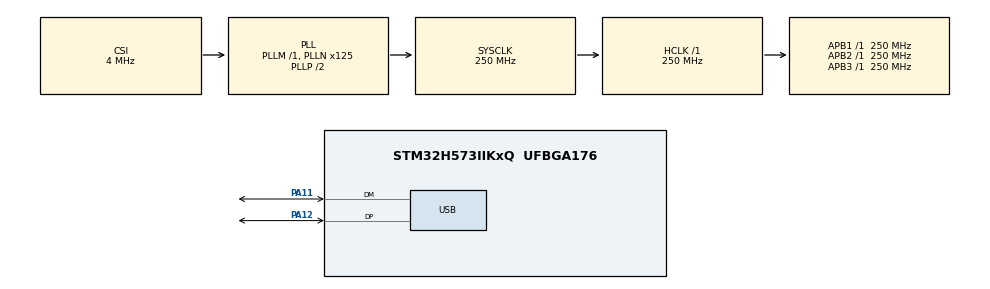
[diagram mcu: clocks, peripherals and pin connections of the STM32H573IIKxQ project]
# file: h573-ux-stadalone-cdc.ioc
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CORTEX_M33_NS.userName=CORTEX_M33
Mcu.Family=STM32H5
Mcu.Name=STM32H573IIKxQ
Mcu.Package=UFBGA176
NVIC.PriorityGroup=NVIC_PRIORITYGROUP_4
NVIC.USB_DRD_FS_IRQn=true\:0\:0\:false\:false\:true\:true\:true\:true
PA11.Mode=Device
PA11.Signal=USB_DM
PA12.Mode=Device
PA12.Signal=USB_DP
ProjectManager.HeapSize=0x200
ProjectManager.StackSize=0x400
ProjectManager.TargetToolchain=STM32CubeIDE
RCC.ADCFreq_Value=250000000
RCC.AHBFreq_Value=250000000
RCC.APB1Freq_Value=250000000
RCC.APB1TimFreq_Value=250000000
RCC.APB2Freq_Value=250000000
RCC.APB2TimFreq_Value=250000000
RCC.APB3Freq_Value=250000000
RCC.CSI_VALUE=4000000
RCC.CortexFreq_Value=250000000
RCC.EPOD_VALUE=4000000
RCC.HCLKFreq_Value=250000000
RCC.HSE_VALUE=25000000
RCC.HSI48_VALUE=48000000
RCC.HSI_VALUE=64000000
RCC.LSE_VALUE=32768
RCC.LSIRC_VALUE=32000
RCC.PLLN=125
RCC.SYSCLKFreq_VALUE=250000000
RCC.SYSCLKSource=RCC_SYSCLKSOURCE_PLLCLK
RCC.USBFreq_Value=48000000
RCC.VCOOutputFreq_Value=500000000
USB.VirtualMode=Device_Only
USBX.BSP.number=1
USBX.Core_System=1
USBX.USBD_CDCACM_EPIN_ADDR=2
USBX.USBD_CDCACM_EPOUT_ADDR=3
USBX.USBX_DEVICE_SYS_SIZE=8*1024
USBX.UX_DEVICE_APP_MEM_POOL_SIZE_STANDALONE=12*1024
USBX.UX_DEVICE_CDC_ACM=1
USBX.UX_Device_Controller=1
USBX.UX_Device_CoreStack=1
USBX0.BSP.STBoard=false
USBX0.BSP.api=Unknown
USBX0.BSP.instance=USB
USBX0.BSP.ip=USB
USBX0.BSP.mode=Device_Only
USBX0.BSP.name=USB_Device
USBX0.BSP.solution=USB
VP_BOOTPATH_VS_BOOTPATH.Mode=BP_Activate
VP_CORTEX_M33_NS_VS_Hclk.Mode=Hclk_Mode
VP_MEMORYMAP_VS_MEMORYMAP.Mode=CurAppReg
VP_PWR_VS_LPOM.Mode=PowerOptimisation
VP_PWR_VS_SECSignals.Mode=Security/Privilege
VP_RCC_USB.Mode=CRS SYNC Source USB
VP_USBX_Core_System.Mode=Core_System
VP_USBX_UX\ Device\ CDC\ ACM\ Class_FS.Mode=UX_Device_class_CDC_ACM_FS
VP_USBX_UX\ Device\ Controller_FS.Mode=UX_Device_Controller_FS
VP_USBX_UX\ Device\ CoreStack_FS.Mode=UX_Device_CoreStack_FS
board=custom

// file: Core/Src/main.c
/* USER CODE BEGIN Header */
/**
 ******************************************************************************
 * @file           : main.c
 * @brief          : Main program body
 ******************************************************************************
 * @attention
 *
 * Copyright (c) 2025 STMicroelectronics.
 * All rights reserved.
 *
 * This software is licensed under terms that can be found in the LICENSE file
 * in the root directory of this software component.
 * If no LICENSE file comes with this software, it is provided AS-IS.
 *
 ******************************************************************************
 */
/* USER CODE END Header */
#include "main.h"
#include "app_usbx_device.h"

/* USER CODE BEGIN Includes */
UX_SLAVE_CLASS_CDC_ACM *cdc_acm = UX_NULL;
/* USER CODE END Includes */

/* USER CODE BEGIN PTD */
uint8_t UserRxBuffer[64];
ULONG rx_actual_length;
/* USER CODE END PTD */

PCD_HandleTypeDef hpcd_USB_DRD_FS;

void SystemClock_Config(void);
static void MX_GPIO_Init(void);

int main(void)
{

	/* MCU Configuration--------------------------------------------------------*/

	/* Reset of all peripherals, Initializes the Flash interface and the Systick. */
	HAL_Init();

	/* Configure the system clock */
	SystemClock_Config();

	/* Initialize all configured peripherals */
	MX_GPIO_Init();
	MX_USBX_Device_Init();

	/* Infinite loop */
	while (1)
	{
		ux_device_stack_tasks_run();
		if(cdc_acm != UX_NULL)
		{
			rx_actual_length = 0;
			ux_device_class_cdc_acm_read_run(cdc_acm, (UCHAR *)UserRxBuffer, 4, &rx_actual_length);
			__NOP();
			if((rx_actual_length>0) && (rx_actual_length<65)){
				ULONG actual_length;
				UINT status = ux_device_class_cdc_acm_write_run(cdc_acm, (UCHAR *)UserRxBuffer, rx_actual_length, &actual_length);
				while(status == UX_STATE_WAIT){//wait for sending
					status =ux_device_class_cdc_acm_write_run(cdc_acm, UX_NULL, 0, &actual_length);
				}
			}

		}
	}
}

void SystemClock_Config(void)
{
	RCC_OscInitTypeDef RCC_OscInitStruct = {0};
	RCC_ClkInitTypeDef RCC_ClkInitStruct = {0};
	RCC_CRSInitTypeDef RCC_CRSInitStruct = {0};

	/** Configure the main internal regulator output voltage
	 */
	__HAL_PWR_VOLTAGESCALING_CONFIG(PWR_REGULATOR_VOLTAGE_SCALE0);

	while(!__HAL_PWR_GET_FLAG(PWR_FLAG_VOSRDY)) {}

	/** Initializes the RCC Oscillators according to the specified parameters
	 * in the RCC_OscInitTypeDef structure.
	 */
	RCC_OscInitStruct.OscillatorType = RCC_OSCILLATORTYPE_HSI48|RCC_OSCILLATORTYPE_CSI;
	RCC_OscInitStruct.HSI48State = RCC_HSI48_ON;
	RCC_OscInitStruct.CSIState = RCC_CSI_ON;
	RCC_OscInitStruct.CSICalibrationValue = RCC_CSICALIBRATION_DEFAULT;
	RCC_OscInitStruct.PLL.PLLState = RCC_PLL_ON;
	RCC_OscInitStruct.PLL.PLLSource = RCC_PLL1_SOURCE_CSI;
	RCC_OscInitStruct.PLL.PLLM = 1;
	RCC_OscInitStruct.PLL.PLLN = 125;
	RCC_OscInitStruct.PLL.PLLP = 2;
	RCC_OscInitStruct.PLL.PLLQ = 2;
	RCC_OscInitStruct.PLL.PLLR = 2;
	RCC_OscInitStruct.PLL.PLLRGE = RCC_PLL1_VCIRANGE_2;
	RCC_OscInitStruct.PLL.PLLVCOSEL = RCC_PLL1_VCORANGE_WIDE;
	RCC_OscInitStruct.PLL.PLLFRACN = 0;
	if (HAL_RCC_OscConfig(&RCC_OscInitStruct) != HAL_OK)
	{
		Error_Handler();
	}

	/** Initializes the CPU, AHB and APB buses clocks
	 */
	RCC_ClkInitStruct.ClockType = RCC_CLOCKTYPE_HCLK|RCC_CLOCKTYPE_SYSCLK
			|RCC_CLOCKTYPE_PCLK1|RCC_CLOCKTYPE_PCLK2
			|RCC_CLOCKTYPE_PCLK3;
	RCC_ClkInitStruct.SYSCLKSource = RCC_SYSCLKSOURCE_PLLCLK;
	RCC_ClkInitStruct.AHBCLKDivider = RCC_SYSCLK_DIV1;
	RCC_ClkInitStruct.APB1CLKDivider = RCC_HCLK_DIV1;
	RCC_ClkInitStruct.APB2CLKDivider = RCC_HCLK_DIV1;
	RCC_ClkInitStruct.APB3CLKDivider = RCC_HCLK_DIV1;

	if (HAL_RCC_ClockConfig(&RCC_ClkInitStruct, FLASH_LATENCY_5) != HAL_OK)
	{
		Error_Handler();
	}

	/** Enable the CRS APB clock
	 */
	__HAL_RCC_CRS_CLK_ENABLE();

	/** Configures CRS
	 */
	RCC_CRSInitStruct.Prescaler = RCC_CRS_SYNC_DIV1;
	RCC_CRSInitStruct.Source = RCC_CRS_SYNC_SOURCE_USB;
	RCC_CRSInitStruct.Polarity = RCC_CRS_SYNC_POLARITY_RISING;
	RCC_CRSInitStruct.ReloadValue = __HAL_RCC_CRS_RELOADVALUE_CALCULATE(48000000,1000);
	RCC_CRSInitStruct.ErrorLimitValue = 34;
	RCC_CRSInitStruct.HSI48CalibrationValue = 32;

	HAL_RCCEx_CRSConfig(&RCC_CRSInitStruct);

	/** Configure the programming delay
	 */
	__HAL_FLASH_SET_PROGRAM_DELAY(FLASH_PROGRAMMING_DELAY_2);
}

void MX_USB_PCD_Init(void)
{

	hpcd_USB_DRD_FS.Instance = USB_DRD_FS;
	hpcd_USB_DRD_FS.Init.dev_endpoints = 8;
	hpcd_USB_DRD_FS.Init.speed = USBD_FS_SPEED;
	hpcd_USB_DRD_FS.Init.phy_itface = PCD_PHY_EMBEDDED;
	hpcd_USB_DRD_FS.Init.Sof_enable = DISABLE;
	hpcd_USB_DRD_FS.Init.low_power_enable = DISABLE;
	hpcd_USB_DRD_FS.Init.lpm_enable = DISABLE;
	hpcd_USB_DRD_FS.Init.battery_charging_enable = DISABLE;
	hpcd_USB_DRD_FS.Init.vbus_sensing_enable = DISABLE;
	hpcd_USB_DRD_FS.Init.bulk_doublebuffer_enable = DISABLE;
	hpcd_USB_DRD_FS.Init.iso_singlebuffer_enable = DISABLE;
	if (HAL_PCD_Init(&hpcd_USB_DRD_FS) != HAL_OK)
	{
		Error_Handler();
	}
	/* USER CODE BEGIN USB_Init 2 */
	HAL_PCDEx_PMAConfig(&hpcd_USB_DRD_FS, 0x00 , PCD_SNG_BUF, 0x40);
	HAL_PCDEx_PMAConfig(&hpcd_USB_DRD_FS, 0x80 , PCD_SNG_BUF, 0x80);
	HAL_PCDEx_PMAConfig(&hpcd_USB_DRD_FS, 0x01, PCD_SNG_BUF, 0xC0);
	HAL_PCDEx_PMAConfig(&hpcd_USB_DRD_FS, 0x81, PCD_SNG_BUF, 0x100);
	HAL_PCDEx_PMAConfig(&hpcd_USB_DRD_FS, 0x82, PCD_SNG_BUF, 0x140);
	ux_dcd_stm32_initialize((ULONG)USB_DRD_FS, (ULONG)&hpcd_USB_DRD_FS);
	HAL_PCD_Start(&hpcd_USB_DRD_FS);
	/* USER CODE END USB_Init 2 */

}

static void MX_GPIO_Init(void)
{

	/* GPIO Ports Clock Enable */
	__HAL_RCC_GPIOA_CLK_ENABLE();

}

void Error_Handler(void)
{
	__disable_irq();
	while (1)
	{
	}
}
